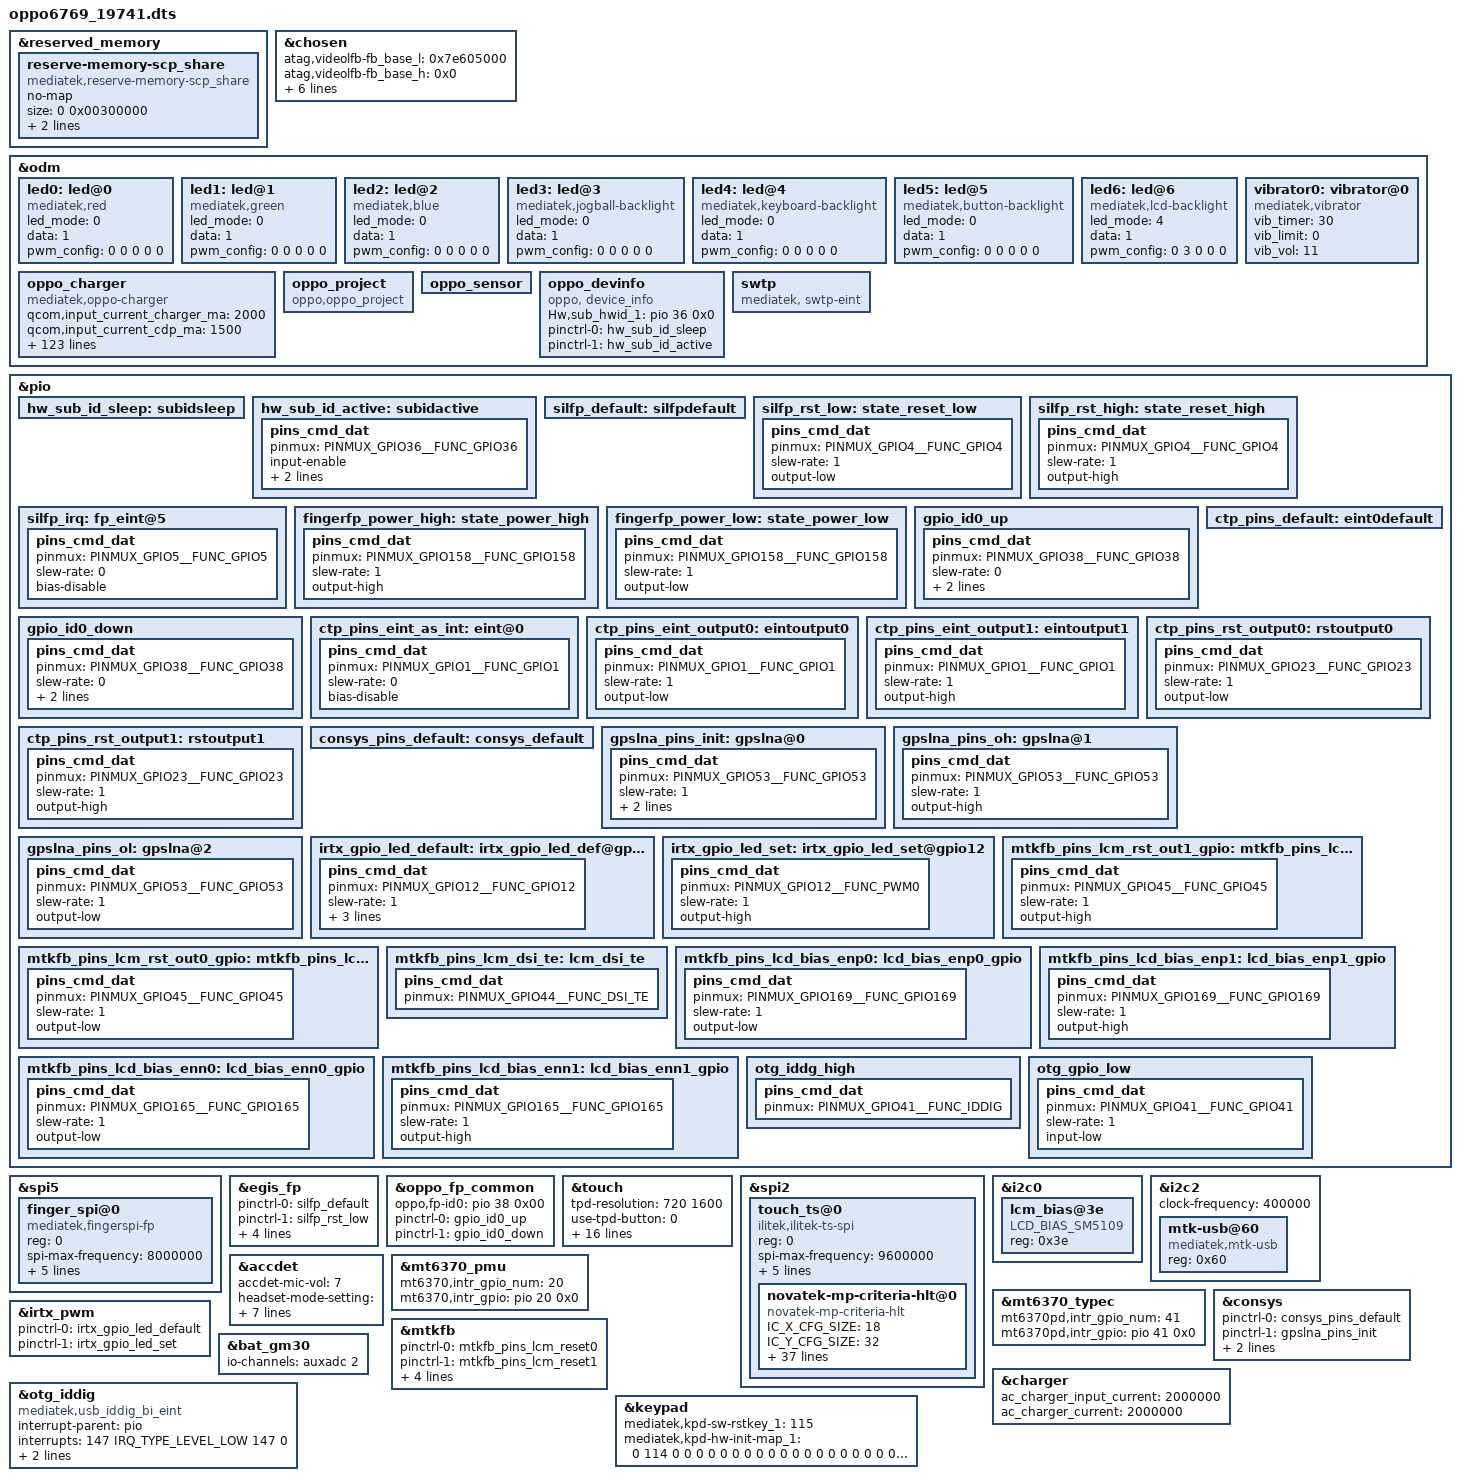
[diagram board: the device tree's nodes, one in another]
/*
 * Copyright (C) 2019 MediaTek Inc.
 *
 * This program is free software; you can redistribute it and/or modify
 * it under the terms of the GNU General Public License version 2 as
 * published by the Free Software Foundation.
 *
 * This program is distributed in the hope that it will be useful,
 * but WITHOUT ANY WARRANTY; without even the implied warranty of
 * MERCHANTABILITY or FITNESS FOR A PARTICULAR PURPOSE.
 * See http://www.gnu.org/licenses/gpl-2.0.html for more details.
 */

/dts-v1/;
/plugin/;
#include <dt-bindings/interrupt-controller/irq.h>
#include <dt-bindings/interrupt-controller/arm-gic.h>
#include <dt-bindings/pinctrl/mt6768-pinfunc.h>

&reserved_memory {
	reserve-memory-scp_share {
		compatible = "mediatek,reserve-memory-scp_share";
		no-map;
		size = <0 0x00300000>;
		alignment = <0 0x1000000>;
		alloc-ranges = <0 0x40000000 0 0x50000000>;
	};
};

/* chosen */
&chosen {

	atag,videolfb-fb_base_l = <0x7e605000>;
	atag,videolfb-fb_base_h = <0x0>;
	atag,videolfb-islcmfound = <1>;
	atag,videolfb-islcm_inited = <0>;
	atag,videolfb-fps= <6000>;
	atag,videolfb-vramSize= <0x017e8000>;
	atag,videolfb-lcmname=
		"hx83112b_fhdp_dsi_cmd_auo_rt5081_drv";
};

&odm {
	led0:led@0 {
		compatible = "mediatek,red";
		led_mode = <0>;
		data = <1>;
		pwm_config = <0 0 0 0 0>;
	};
	led1:led@1 {
		compatible = "mediatek,green";
		led_mode = <0>;
		data = <1>;
		pwm_config = <0 0 0 0 0>;
	};
	led2:led@2 {
		compatible = "mediatek,blue";
		led_mode = <0>;
		data = <1>;
		pwm_config = <0 0 0 0 0>;
	};
	led3:led@3 {
		compatible = "mediatek,jogball-backlight";
		led_mode = <0>;
		data = <1>;
		pwm_config = <0 0 0 0 0>;
	};
	led4:led@4 {
		compatible = "mediatek,keyboard-backlight";
		led_mode = <0>;
		data = <1>;
		pwm_config = <0 0 0 0 0>;
	};
	led5:led@5 {
		compatible = "mediatek,button-backlight";
		led_mode = <0>;
		data = <1>;
		pwm_config = <0 0 0 0 0>;
	};
	led6:led@6 {
		compatible = "mediatek,lcd-backlight";
		led_mode = <4>;
		data = <1>;
		pwm_config = <0 3 0 0 0>;
	};
	vibrator0:vibrator@0 {
		compatible = "mediatek,vibrator";
		/*
		vib_timer = <25>;
		vib_limit = <9>;
		vib_vol= <9>;
		*/
		vib_timer = <30>; /*xing.xiong@BSP.Kernel.Driver, 2018/12/08, Add for vibrator*/
		vib_limit = <0>;
		vib_vol= <11>;
	};
//#ifdef ODM_WT_EDIT
/*Sidong.Zhao@ODM_WT.BSP.CHG 2019/11/4,add oppo charge framework*/
	oppo_charger: oppo_charger {
		compatible = "mediatek,oppo-charger";
		//pinctrl-names = "default", "charger_gpio_as_output_low", "charger_gpio_as_output_high", "ship_sleep", "ship_active", "shortc_active";
		//pinctrl-0 = <&charger_pins_default>;
		//pinctrl-1 = <&charger_pins_eint_output0>;
		//pinctrl-2 = <&charger_pins_eint_output1>;
		//pinctrl-3 = <&ship_sleep_gpio>;
		//pinctrl-4 = <&ship_active_gpio>;
		//pinctrl-5 = <&shortc_active_gpio>;

		//for oppo chg framework:
		qcom,input_current_charger_ma = <2000>;
		qcom,input_current_cdp_ma = <1500>;
		qcom,input_current_usb_ma = <500>;
		qcom,input_current_led_ma = <1200>;
		qcom,input_current_led_ma_forcmcc = <500>;
		qcom,input_current_camera_ma = <1200>;
		qcom,input_current_calling_ma = <1200>;
		
		qcom,input_current_led_ma_high = <1200>;
		qcom,input_current_led_ma_warm = <1500>;
		qcom,input_current_led_ma_normal = <2000>;

		qcom,led_high_bat_decidegc = <370>;
		qcom,led_warm_bat_decidegc = <350>;

		qcom,iterm_disabled = <0>;
		qcom,iterm_ma = <265>;
		qcom,recharge-mv = <115>;

		qcom,batt_capacity_mah = <5000>; /*typical capacity*/
		//qcom,batt_capacity_mah = <3900>; /*rated capacity*/

		qcom,removed_bat_decidegc = <190>;  /* < -19C */

		qcom,cold_bat_decidegc = <20>;  /* -2C ~ 0C */
		qcom,temp_cold_vfloat_mv = <3980>;
		qcom,temp_cold_fastchg_current_ma = <350>;

		qcom,little_cold_bat_decidegc = <0>;	/* 0C ~ 5C */
		qcom,temp_little_cold_vfloat_mv = <4435>;
		qcom,temp_little_cold_fastchg_current_ma_high = <650>;
		qcom,temp_little_cold_fastchg_current_ma_low = <650>;
		qcom,temp_little_cold_fastchg_current_ma = <650>;
		monet,temp_little_cold_usbchg_current_ma_high = <650>;
		monet,temp_little_cold_usbchg_current_ma_low = <650>;
		monet,temp_little_cold_usbchg_current_ma = <650>;

		qcom,cool_bat_decidegc = <50>;	/* 5C ~ 12C */
		qcom,temp_cool_vfloat_mv = <4435>;
		qcom,temp_cool_fastchg_current_ma_high = <1350>;
		qcom,temp_cool_fastchg_current_ma_low = <650>;
		monet,temp_cool_usbchg_current_ma_high = <650>;
		monet,temp_cool_usbchg_current_ma_low = <550>;

		qcom,little_cool_bat_decidegc = <120>;	/* 12C ~ 16C */
		qcom,temp_little_cool_vfloat_mv = <4435>;
		qcom,temp_little_cool_fastchg_current_ma = <2050>;
		monet,temp_little_cool_usbchg_current_ma = <550>;

		qcom,normal_bat_decidegc = <160>;	/* 16C ~ 45C */
		qcom,temp_normal_fastchg_current_ma = <2200>;
		monet,temp_normal_usbchg_current_ma = <550>;
		qcom,temp_normal_vfloat_mv = <4435>;

		qcom,warm_bat_decidegc = <440>;		/* 44C ~ 53C */ /*8pin Bat Vooc project need add 3 degree C*/
		qcom,temp_warm_vfloat_mv = <4130>;
		qcom,temp_warm_fastchg_current_ma = <1350>;
		monet,temp_warm_usbchg_current_ma = <550>;
		qcom,temp_warm_fastchg_current_ma_led_on = <500>;

		qcom,hot_bat_decidegc = <530>;  /* > 53C */

		qcom,non_standard_vfloat_mv = <3980>;
		qcom,non_standard_fastchg_current_ma = <512>;

		qcom,short_c_bat_cv_mv = <4330>;
		qcom,short_c_bat_vfloat_mv = <3800>;
		qcom,short_c_bat_fastchg_current_ma = <512>;
		qcom,short_c_bat_vfloat_sw_limit = <3750>;

		qcom,cold_vfloat_sw_limit = <3930>;
		qcom,little_cold_vfloat_sw_limit = <4380>;
		qcom,cool_vfloat_sw_limit = <4380>;
		qcom,little_cool_vfloat_sw_limit = <4380>;
		qcom,normal_vfloat_sw_limit = <4380>;
		qcom,warm_vfloat_sw_limit = <4080>;
		qcom,non_standard_vfloat_sw_limit = <3930>;

		qcom,max_chg_time_sec = <36000>;
		qcom,charger_hv_thr = <5800>;
		qcom,charger_recv_thr = <5800>;
		qcom,charger_lv_thr = <3400>;
		qcom,vbatt_full_thr = <4400>;
		qcom,vbatt_hv_thr = <4550>;

		qcom,vfloat_step_mv = <10>;
		qcom,non_standard_vfloat_over_sw_limit = <4000>;
		qcom,cold_vfloat_over_sw_limit = <4000>;
		qcom,little_cold_vfloat_over_sw_limit = <4450>;
		qcom,cool_vfloat_over_sw_limit = <4450>;
		qcom,little_cool_vfloat_over_sw_limit = <4450>;
		qcom,normal_vfloat_over_sw_limit = <4450>;
		qcom,warm_vfloat_over_sw_limit = <4150>;

		qcom,vbatt_power_off = <3300>;
		qcom,vbatt_soc_1 = <3410>;
		qcom,vooc_project = <0>;
		qcom,vbatt_num = <1>;

		qcom,normal_vterm_hw_inc = <150>;
		qcom,non_normal_vterm_hw_inc = <10>;

		qcom,ff1_normal_fastchg_ma = <1088>;
		qcom,ffc2_normal_fastchg_ma = <780>;/*16C~35c*/
		qcom,ffc2_temp_warm_decidegc = <350>;
		qcom,ffc2_warm_fastchg_ma = <840>;/*35C~40c*/
		qcom,ffc2_temp_high_decidegc = <400>;
		qcom,ffc2_temp_low_decidegc = <120>;
		qcom,ff1_exit_step_ma = <488>;
		qcom,ff1_warm_exit_step_ma = <418>;
		qcom,ffc2_exit_step_ma = <180>;
		qcom,ffc2_warm_exit_step_ma = <170>;

		qcom,ffc_normal_vfloat_sw_limit = <4430>;
		qcom,ffc_temp_normal_vfloat_mv = <4500>;
		qcom,ffc_normal_vfloat_over_sw_limit = <4500>;

		qcom,default_iterm_ma = <265>;
		qcom,default_temp_normal_fastchg_current_ma = <2200>;
		qcom,default_normal_vfloat_sw_limit = <4380>;
		qcom,default_temp_normal_vfloat_mv = <4435>;
		qcom,default_normal_vfloat_over_sw_limit = <4450>;

		//for 2nd chip:
		qcom,iterm_ma_2nd = <300>;
		qcom,recharge-mv_2nd = <121>;

		qcom,temp_little_cold_vfloat_mv_2nd = <4391>;	/* 0C ~ 5C */
		qcom,temp_cool_vfloat_mv_2nd = <4391>;	/* 5C ~ 12C */
		qcom,temp_little_cool_vfloat_mv_2nd = <4391>;	/* 12C ~ 16C */
		qcom,temp_normal_vfloat_mv_2nd = <4391>;	/* 16C ~ 45C */

		qcom,little_cold_vfloat_over_sw_limit_2nd = <4395>;
		qcom,cool_vfloat_over_sw_limit_2nd = <4395>;
		qcom,little_cool_vfloat_over_sw_limit_2nd = <4395>;
		qcom,normal_vfloat_over_sw_limit_2nd = <4395>;

		qcom,default_iterm_ma_2nd = <300>;
		qcom,default_temp_normal_vfloat_mv_2nd = <4391>;
		qcom,default_normal_vfloat_over_sw_limit_2nd = <4395>;

		//for control:
		//qcom,suspend_after_full;
		qcom,check_batt_full_by_sw;
		//qcom,external_gauge;
		qcom,chg_ctrl_by_calling;
		qcom,chg_ctrl_by_lcd;
		qcom,chg_ctrl_by_camera;
		qcom,sw_vfloat_over_protect_enable;
		//qcom,ffc_support;

		//GPIO config:
		//qcom,chargerid_switch-gpio = <&pio 97 0x00>;
		//qcom,ship-gpio = <&pio 155 0x00>;
		//qcom,shortc-gpio = <&pio 77 0x00>;
	};
//#endif /*ODM_WT_EDIT*/
//#ifdef VENDOR_EDIT
/*Bin.Li@EXP.BSP.bootloader.bootflow, 2017/05/15, Add for oppo project */
	oppo_project:oppo_project {
		compatible = "oppo,oppo_project";
	};
//#endif /*VENDOR_EDIT*/
//#ifdef VENDOR_EDIT
/*Fei.Mo@PSW.BSP.Sensor, 2017/12/18, Add for sensor calibration paramaters */
       oppo_sensor:oppo_sensor {
       };
//#endif /*VENDOR_EDIT*

//#ifdef ODM_WT_EDIT
/*Junbo.Guo@ODM_WT.BSP.Kernel.Boot, 2019/10/29, Add for hardware id */
	oppo_devinfo:oppo_devinfo {
		compatible = "oppo, device_info";
		Hw,sub_hwid_1 =<&pio 36 0x0>;
		pinctrl-names = "hw_sub_id_sleep", "hw_sub_id_active";
		pinctrl-0 = <&hw_sub_id_sleep>;
		pinctrl-1 = <&hw_sub_id_active>;
		status = "okay";
	};
//#endif /*ODM_WT_EDIT*	
//#ifdef ODM_WT_EDIT
/*Yong.Cheng@ODM_WT.NW.RF.swtp, 2019/12/10, Add for swtp, RF cable detect */
	swtp:swtp {
		compatible = "mediatek, swtp-eint";
	};
//#endif /*ODM_WT_EDIT*	/
};

//#ifdef ODM_WT_EDIT
/*Junbo.Guo@ODM_WT.BSP.Kernel.Boot, 2019/10/29, Add for hardware id */
&pio{
	hw_sub_id_sleep: subidsleep {
	};
	hw_sub_id_active: subidactive {
		pins_cmd_dat {
			pinmux = <PINMUX_GPIO36__FUNC_GPIO36>;
			input-enable;
			slew-rate = <0>;
			bias-disable;
		};
	};
};
//#endif /*ODM_WT_EDIT*

//#ifdef VENDOR_EDIT
//Qingwen.Liu@RM.BSP.Fingerprint.Basic 2019/1/26 add for fpc fingerprint driver start
&spi5 {
	#address-cells = <1>;
	#size-cells = <0>;
	status = "okay";
	finger_spi@0 {
	    compatible = "mediatek,fingerspi-fp";
	    reg = <0>;
	    spi-max-frequency = <8000000>;
	    netlink-event = <30>;
	    spi-id = <1>;
	    spi-irq = <5>;
	    spi-reg = <0x11015000>;
	    spi-avdd-gpio = <158>;
        status = "okay";
    };
};

&egis_fp {
	pinctrl-names = "default", "rst-low", "rst-high",
	                "irq-init", "power_high","power_low";
	pinctrl-0 = <&silfp_default>;
	pinctrl-1 = <&silfp_rst_low>;
	pinctrl-2 = <&silfp_rst_high>;
	pinctrl-3 = <&silfp_irq>;
	pinctrl-4 = <&fingerfp_power_high>;
	pinctrl-5 = <&fingerfp_power_low>;
	status = "okay";
};

&pio {
	silfp_default: silfpdefault {
	};
	silfp_rst_low: state_reset_low {
		pins_cmd_dat {
			pinmux = <PINMUX_GPIO4__FUNC_GPIO4>;
			slew-rate = <1>;
			output-low;
		};
	};
	silfp_rst_high: state_reset_high {
		pins_cmd_dat {
			pinmux = <PINMUX_GPIO4__FUNC_GPIO4>;
			slew-rate = <1>;
			output-high;
		};
	};
	silfp_irq: fp_eint@5 {
		pins_cmd_dat {
			pinmux = <PINMUX_GPIO5__FUNC_GPIO5>;
			slew-rate = <0>;
			bias-disable;
		};
	};
	fingerfp_power_high: state_power_high {
		pins_cmd_dat {
			pinmux = <PINMUX_GPIO158__FUNC_GPIO158>;
			slew-rate = <1>;
			output-high;
		};
	};

	fingerfp_power_low: state_power_low {
		pins_cmd_dat {
			pinmux = <PINMUX_GPIO158__FUNC_GPIO158>;
			slew-rate = <1>;
			output-low;
		};
	};
};

/*the id config to project dts.*/
&pio{
	gpio_id0_up: gpio_id0_up {
		pins_cmd_dat {
			pinmux = <PINMUX_GPIO38__FUNC_GPIO38>;
			slew-rate = <0>;
			bias-pull-up;
			input-enable;
		};
	};
	gpio_id0_down: gpio_id0_down {
		pins_cmd_dat {
			pinmux = <PINMUX_GPIO38__FUNC_GPIO38>;
			slew-rate = <0>;
			bias-pull-down;
			input-enable;
		};
	};
};

&oppo_fp_common {
	oppo,fp-id0 = <&pio 38 0x00>;
	pinctrl-names = "gpio_id0_up","gpio_id0_down";
	pinctrl-0 = <&gpio_id0_up>;
	pinctrl-1 = <&gpio_id0_down>;
	status = "okay";
};
//Qingwen.Liu@RM.BSP.Fingerprint.Basic 2019/1/26 add for fpc fingerprint driver end
//#endif //VENDOR_EDIT

/* TOUCH start */
&touch {
	tpd-resolution = <720 1600>;
	use-tpd-button = <0>;
	tpd-key-num = <3>;
	tpd-key-local= <139 172 158 0>;
	tpd-key-dim-local = <90 883 100 40 230
				883 100 40 370 883 100 40 0 0 0 0>;
	tpd-max-touch-num = <10>;
	tpd-filter-enable = <0>;
	tpd-filter-pixel-density = <168>;
	tpd-filter-custom-prameters = <0 0 0 0 0 0 0 0 0 0 0 0>;
	tpd-filter-custom-speed = <0 0 0>;
	pinctrl-names = "default", "state_eint_as_int",
		"state_eint_output0", "state_eint_output1",
		"state_rst_output0", "state_rst_output1";
	pinctrl-0 = <&ctp_pins_default>;
	pinctrl-1 = <&ctp_pins_eint_as_int>;
	pinctrl-2 = <&ctp_pins_eint_output0>;
	pinctrl-3 = <&ctp_pins_eint_output1>;
	pinctrl-4 = <&ctp_pins_rst_output0>;
	pinctrl-5 = <&ctp_pins_rst_output1>;
	status = "okay";
};
&pio {
	ctp_pins_default: eint0default {
	};
	ctp_pins_eint_as_int: eint@0 {
		pins_cmd_dat {
			pinmux = <PINMUX_GPIO1__FUNC_GPIO1>;
			slew-rate = <0>;
			bias-disable;
		};
	};
	ctp_pins_eint_output0: eintoutput0 {
		pins_cmd_dat {
			pinmux = <PINMUX_GPIO1__FUNC_GPIO1>;
			slew-rate = <1>;
			output-low;
		};
	};
	ctp_pins_eint_output1: eintoutput1 {
		pins_cmd_dat {
			pinmux = <PINMUX_GPIO1__FUNC_GPIO1>;
			slew-rate = <1>;
			output-high;
	};
	};
	ctp_pins_rst_output0: rstoutput0 {
		pins_cmd_dat {
			pinmux = <PINMUX_GPIO23__FUNC_GPIO23>;
			slew-rate = <1>;
			output-low;
		};
	};
	ctp_pins_rst_output1: rstoutput1 {
		pins_cmd_dat {
			pinmux = <PINMUX_GPIO23__FUNC_GPIO23>;
			slew-rate = <1>;
			output-high;
		};
	};
};
//#ifdef ODM_WT_EDIT
//#Tongxing.Liu@ODM_WT.BSP.Touchscreen.Base,2019/10/04,bringup add for xl and hlt touchscreen mould dts config.
&spi2 {
    #address-cells = <1>;
    #size-cells = <0>;
    touch_ts@0 {
        reg = <0>;
        compatible = "ilitek,ilitek-ts-spi","novatek,NVT-ts-spi";
	status = "okay";
	/* touch spi config */
        spi-max-frequency = <9600000>;
	/* novatek touch gpio config */
	novatek,irq-gpio = <&pio 1 0>;
	novatek,reset-gpio = <&pio 23 0>;
	novatek,reset_global_gpio = <&pio 45 0>;
	/* 672A, 525B */
	novatek,swrst-n8-addr = <0x03F0FE>;
	/* MP config  */
	novatek,mp-support-dt;
	novatek-mp-criteria-hlt@0 {
		#address-cells = <1>;
		#size-cells = <0>;
		compatible = "novatek-mp-criteria-hlt";
	        /* MP Config */
		IC_X_CFG_SIZE = <18>;
		IC_Y_CFG_SIZE = <32>;
		IC_KEY_CFG_SIZE = <4>;
		X_Channel = <18>;
		Y_Channel = <32>;
		AIN_X = <0 1 2 3 4 5 6 7 8 9 10 11 12 13 14 15 16 17>;
		AIN_Y = <0 1 2 3 4 5 6 7 8 9 10 11 12 13 14 15 16 17 18 19
							20 21 22 23 24 25 26 27 28 29 30 31>;
		AIN_KEY = <0 1 2 0xFF>;

		/* MP Criteria */
		PS_Config_Lmt_Short_Rawdata_P = <
			14008 14008 14008 14008 14008 14008 14008 14008 14008 14008 14008 14008 14008 14008 14008 14008 14008 14008
			14008 14008 14008 14008 14008 14008 14008 14008 14008 14008 14008 14008 14008 14008 14008 14008 14008 14008
			14008 14008 14008 14008 14008 14008 14008 14008 14008 14008 14008 14008 14008 14008 14008 14008 14008 14008
			14008 14008 14008 14008 14008 14008 14008 14008 14008 14008 14008 14008 14008 14008 14008 14008 14008 14008
			14008 14008 14008 14008 14008 14008 14008 14008 14008 14008 14008 14008 14008 14008 14008 14008 14008 14008
			14008 14008 14008 14008 14008 14008 14008 14008 14008 14008 14008 14008 14008 14008 14008 14008 14008 14008
			14008 14008 14008 14008 14008 14008 14008 14008 14008 14008 14008 14008 14008 14008 14008 14008 14008 14008
			14008 14008 14008 14008 14008 14008 14008 14008 14008 14008 14008 14008 14008 14008 14008 14008 14008 14008
			14008 14008 14008 14008 14008 14008 14008 14008 14008 14008 14008 14008 14008 14008 14008 14008 14008 14008
			14008 14008 14008 14008 14008 14008 14008 14008 14008 14008 14008 14008 14008 14008 14008 14008 14008 14008
			14008 14008 14008 14008 14008 14008 14008 14008 14008 14008 14008 14008 14008 14008 14008 14008 14008 14008
			14008 14008 14008 14008 14008 14008 14008 14008 14008 14008 14008 14008 14008 14008 14008 14008 14008 14008
			14008 14008 14008 14008 14008 14008 14008 14008 14008 14008 14008 14008 14008 14008 14008 14008 14008 14008
			14008 14008 14008 14008 14008 14008 14008 14008 14008 14008 14008 14008 14008 14008 14008 14008 14008 14008
			14008 14008 14008 14008 14008 14008 14008 14008 14008 14008 14008 14008 14008 14008 14008 14008 14008 14008
			14008 14008 14008 14008 14008 14008 14008 14008 14008 14008 14008 14008 14008 14008 14008 14008 14008 14008
			14008 14008 14008 14008 14008 14008 14008 14008 14008 14008 14008 14008 14008 14008 14008 14008 14008 14008
			14008 14008 14008 14008 14008 14008 14008 14008 14008 14008 14008 14008 14008 14008 14008 14008 14008 14008
			14008 14008 14008 14008 14008 14008 14008 14008 14008 14008 14008 14008 14008 14008 14008 14008 14008 14008
			14008 14008 14008 14008 14008 14008 14008 14008 14008 14008 14008 14008 14008 14008 14008 14008 14008 14008
			14008 14008 14008 14008 14008 14008 14008 14008 14008 14008 14008 14008 14008 14008 14008 14008 14008 14008
			14008 14008 14008 14008 14008 14008 14008 14008 14008 14008 14008 14008 14008 14008 14008 14008 14008 14008
			14008 14008 14008 14008 14008 14008 14008 14008 14008 14008 14008 14008 14008 14008 14008 14008 14008 14008
			14008 14008 14008 14008 14008 14008 14008 14008 14008 14008 14008 14008 14008 14008 14008 14008 14008 14008
			14008 14008 14008 14008 14008 14008 14008 14008 14008 14008 14008 14008 14008 14008 14008 14008 14008 14008
			14008 14008 14008 14008 14008 14008 14008 14008 14008 14008 14008 14008 14008 14008 14008 14008 14008 14008
			14008 14008 14008 14008 14008 14008 14008 14008 14008 14008 14008 14008 14008 14008 14008 14008 14008 14008
			14008 14008 14008 14008 14008 14008 14008 14008 14008 14008 14008 14008 14008 14008 14008 14008 14008 14008
			14008 14008 14008 14008 14008 14008 14008 14008 14008 14008 14008 14008 14008 14008 14008 14008 14008 14008
			14008 14008 14008 14008 14008 14008 14008 14008 14008 14008 14008 14008 14008 14008 14008 14008 14008 14008
			14008 14008 14008 14008 14008 14008 14008 14008 14008 14008 14008 14008 14008 14008 14008 14008 14008 14008
			14008 14008 14008 14008 14008 14008 14008 14008 14008 14008 14008 14008 14008 14008 14008 14008 14008 14008
			>;

		PS_Config_Lmt_Short_Rawdata_N = <
			10000 10000 10000 10000 10000 10000 10000 10000 10000 10000 10000 10000 10000 10000 10000 10000 10000 10000
			10000 10000 10000 10000 10000 10000 10000 10000 10000 10000 10000 10000 10000 10000 10000 10000 10000 10000
			10000 10000 10000 10000 10000 10000 10000 10000 10000 10000 10000 10000 10000 10000 10000 10000 10000 10000
			10000 10000 10000 10000 10000 10000 10000 10000 10000 10000 10000 10000 10000 10000 10000 10000 10000 10000
			10000 10000 10000 10000 10000 10000 10000 10000 10000 10000 10000 10000 10000 10000 10000 10000 10000 10000
			10000 10000 10000 10000 10000 10000 10000 10000 10000 10000 10000 10000 10000 10000 10000 10000 10000 10000
			10000 10000 10000 10000 10000 10000 10000 10000 10000 10000 10000 10000 10000 10000 10000 10000 10000 10000
			10000 10000 10000 10000 10000 10000 10000 10000 10000 10000 10000 10000 10000 10000 10000 10000 10000 10000
			10000 10000 10000 10000 10000 10000 10000 10000 10000 10000 10000 10000 10000 10000 10000 10000 10000 10000
			10000 10000 10000 10000 10000 10000 10000 10000 10000 10000 10000 10000 10000 10000 10000 10000 10000 10000
			10000 10000 10000 10000 10000 10000 10000 10000 10000 10000 10000 10000 10000 10000 10000 10000 10000 10000
			10000 10000 10000 10000 10000 10000 10000 10000 10000 10000 10000 10000 10000 10000 10000 10000 10000 10000
			10000 10000 10000 10000 10000 10000 10000 10000 10000 10000 10000 10000 10000 10000 10000 10000 10000 10000
			10000 10000 10000 10000 10000 10000 10000 10000 10000 10000 10000 10000 10000 10000 10000 10000 10000 10000
			10000 10000 10000 10000 10000 10000 10000 10000 10000 10000 10000 10000 10000 10000 10000 10000 10000 10000
			10000 10000 10000 10000 10000 10000 10000 10000 10000 10000 10000 10000 10000 10000 10000 10000 10000 10000
			10000 10000 10000 10000 10000 10000 10000 10000 10000 10000 10000 10000 10000 10000 10000 10000 10000 10000
			10000 10000 10000 10000 10000 10000 10000 10000 10000 10000 10000 10000 10000 10000 10000 10000 10000 10000
			10000 10000 10000 10000 10000 10000 10000 10000 10000 10000 10000 10000 10000 10000 10000 10000 10000 10000
			10000 10000 10000 10000 10000 10000 10000 10000 10000 10000 10000 10000 10000 10000 10000 10000 10000 10000
			10000 10000 10000 10000 10000 10000 10000 10000 10000 10000 10000 10000 10000 10000 10000 10000 10000 10000
			10000 10000 10000 10000 10000 10000 10000 10000 10000 10000 10000 10000 10000 10000 10000 10000 10000 10000
			10000 10000 10000 10000 10000 10000 10000 10000 10000 10000 10000 10000 10000 10000 10000 10000 10000 10000
			10000 10000 10000 10000 10000 10000 10000 10000 10000 10000 10000 10000 10000 10000 10000 10000 10000 10000
			10000 10000 10000 10000 10000 10000 10000 10000 10000 10000 10000 10000 10000 10000 10000 10000 10000 10000
			10000 10000 10000 10000 10000 10000 10000 10000 10000 10000 10000 10000 10000 10000 10000 10000 10000 10000
			10000 10000 10000 10000 10000 10000 10000 10000 10000 10000 10000 10000 10000 10000 10000 10000 10000 10000
			10000 10000 10000 10000 10000 10000 10000 10000 10000 10000 10000 10000 10000 10000 10000 10000 10000 10000
			10000 10000 10000 10000 10000 10000 10000 10000 10000 10000 10000 10000 10000 10000 10000 10000 10000 10000
			10000 10000 10000 10000 10000 10000 10000 10000 10000 10000 10000 10000 10000 10000 10000 10000 10000 10000
			10000 10000 10000 10000 10000 10000 10000 10000 10000 10000 10000 10000 10000 10000 10000 10000 10000 10000
			10000 10000 10000 10000 10000 10000 10000 10000 10000 10000 10000 10000 10000 10000 10000 10000 10000 10000
			>;

		PS_Config_Lmt_Open_Rawdata_P = <
			4096 4096 4096 4096 4096 4096 4096 4096 4096 4096 4096 4096 4096 4096 4096 4096 4096 4096
			4096 4096 4096 4096 4096 4096 4096 4096 4096 4096 4096 4096 4096 4096 4096 4096 4096 4096
			4096 4096 4096 4096 4096 4096 4096 4096 4096 4096 4096 4096 4096 4096 4096 4096 4096 4096
			4096 4096 4096 4096 4096 4096 4096 4096 4096 4096 4096 4096 4096 4096 4096 4096 4096 4096
			4096 4096 4096 4096 4096 4096 4096 4096 4096 4096 4096 4096 4096 4096 4096 4096 4096 4096
			4096 4096 4096 4096 4096 4096 4096 4096 4096 4096 4096 4096 4096 4096 4096 4096 4096 4096
			4096 4096 4096 4096 4096 4096 4096 4096 4096 4096 4096 4096 4096 4096 4096 4096 4096 4096
			4096 4096 4096 4096 4096 4096 4096 4096 4096 4096 4096 4096 4096 4096 4096 4096 4096 4096
			4096 4096 4096 4096 4096 4096 4096 4096 4096 4096 4096 4096 4096 4096 4096 4096 4096 4096
			4096 4096 4096 4096 4096 4096 4096 4096 4096 4096 4096 4096 4096 4096 4096 4096 4096 4096
			4096 4096 4096 4096 4096 4096 4096 4096 4096 4096 4096 4096 4096 4096 4096 4096 4096 4096
			4096 4096 4096 4096 4096 4096 4096 4096 4096 4096 4096 4096 4096 4096 4096 4096 4096 4096
			4096 4096 4096 4096 4096 4096 4096 4096 4096 4096 4096 4096 4096 4096 4096 4096 4096 4096
			4096 4096 4096 4096 4096 4096 4096 4096 4096 4096 4096 4096 4096 4096 4096 4096 4096 4096
			4096 4096 4096 4096 4096 4096 4096 4096 4096 4096 4096 4096 4096 4096 4096 4096 4096 4096
			4096 4096 4096 4096 4096 4096 4096 4096 4096 4096 4096 4096 4096 4096 4096 4096 4096 4096
			4096 4096 4096 4096 4096 4096 4096 4096 4096 4096 4096 4096 4096 4096 4096 4096 4096 4096
			4096 4096 4096 4096 4096 4096 4096 4096 4096 4096 4096 4096 4096 4096 4096 4096 4096 4096
			4096 4096 4096 4096 4096 4096 4096 4096 4096 4096 4096 4096 4096 4096 4096 4096 4096 4096
			4096 4096 4096 4096 4096 4096 4096 4096 4096 4096 4096 4096 4096 4096 4096 4096 4096 4096
			4096 4096 4096 4096 4096 4096 4096 4096 4096 4096 4096 4096 4096 4096 4096 4096 4096 4096
			4096 4096 4096 4096 4096 4096 4096 4096 4096 4096 4096 4096 4096 4096 4096 4096 4096 4096
			4096 4096 4096 4096 4096 4096 4096 4096 4096 4096 4096 4096 4096 4096 4096 4096 4096 4096
			4096 4096 4096 4096 4096 4096 4096 4096 4096 4096 4096 4096 4096 4096 4096 4096 4096 4096
			4096 4096 4096 4096 4096 4096 4096 4096 4096 4096 4096 4096 4096 4096 4096 4096 4096 4096
			4096 4096 4096 4096 4096 4096 4096 4096 4096 4096 4096 4096 4096 4096 4096 4096 4096 4096
			4096 4096 4096 4096 4096 4096 4096 4096 4096 4096 4096 4096 4096 4096 4096 4096 4096 4096
			4096 4096 4096 4096 4096 4096 4096 4096 4096 4096 4096 4096 4096 4096 4096 4096 4096 4096
			4096 4096 4096 4096 4096 4096 4096 4096 4096 4096 4096 4096 4096 4096 4096 4096 4096 4096
			4096 4096 4096 4096 4096 4096 4096 4096 4096 4096 4096 4096 4096 4096 4096 4096 4096 4096
			4096 4096 4096 4096 4096 4096 4096 4096 4096 4096 4096 4096 4096 4096 4096 4096 4096 4096
			4096 4096 4096 4096 4096 4096 4096 4096 4096 4096 4096 4096 4096 4096 4096 4096 4096 4096
			>;

		PS_Config_Lmt_Open_Rawdata_N = <
			50 50 50 50 50 50 50 50 50 50 50 50 50 50 50 50 50 50
			50 50 50 50 50 50 50 50 50 50 50 50 50 50 50 50 50 50
			50 50 50 50 50 50 50 50 50 50 50 50 50 50 50 50 50 50
			50 50 50 50 50 50 50 50 50 50 50 50 50 50 50 50 50 50
			50 50 50 50 50 50 50 50 50 50 50 50 50 50 50 50 50 50
			50 50 50 50 50 50 50 50 50 50 50 50 50 50 50 50 50 50
			50 50 50 50 50 50 50 50 50 50 50 50 50 50 50 50 50 50
			50 50 50 50 50 50 50 50 50 50 50 50 50 50 50 50 50 50
			50 50 50 50 50 50 50 50 50 50 50 50 50 50 50 50 50 50
			50 50 50 50 50 50 50 50 50 50 50 50 50 50 50 50 50 50
			50 50 50 50 50 50 50 50 50 50 50 50 50 50 50 50 50 50
			50 50 50 50 50 50 50 50 50 50 50 50 50 50 50 50 50 50
			50 50 50 50 50 50 50 50 50 50 50 50 50 50 50 50 50 50
			50 50 50 50 50 50 50 50 50 50 50 50 50 50 50 50 50 50
			50 50 50 50 50 50 50 50 50 50 50 50 50 50 50 50 50 50
			50 50 50 50 50 50 50 50 50 50 50 50 50 50 50 50 50 50
			50 50 50 50 50 50 50 50 50 50 50 50 50 50 50 50 50 50
			50 50 50 50 50 50 50 50 50 50 50 50 50 50 50 50 50 50
			50 50 50 50 50 50 50 50 50 50 50 50 50 50 50 50 50 50
			50 50 50 50 50 50 50 50 50 50 50 50 50 50 50 50 50 50
			50 50 50 50 50 50 50 50 50 50 50 50 50 50 50 50 50 50
			50 50 50 50 50 50 50 50 50 50 50 50 50 50 50 50 50 50
			50 50 50 50 50 50 50 50 50 50 50 50 50 50 50 50 50 50
			50 50 50 50 50 50 50 50 50 50 50 50 50 50 50 50 50 50
			50 50 50 50 50 50 50 50 50 50 50 50 50 50 50 50 50 50
			50 50 50 50 50 50 50 50 50 50 50 50 50 50 50 50 50 50
			50 50 50 50 50 50 50 50 50 50 50 50 50 50 50 50 50 50
			50 50 50 50 50 50 50 50 50 50 50 50 50 50 50 50 50 50
			50 50 50 50 50 50 50 50 50 50 50 50 50 50 50 50 50 50
			50 50 50 50 50 50 50 50 50 50 50 50 50 50 50 50 50 50
			50 50 50 50 50 50 50 50 50 50 50 50 50 50 50 50 50 50
			50 50 50 50 50 50 50 50 50 50 50 50 50 50 50 50 50 50
			>;

		PS_Config_Lmt_FW_Rawdata_P = <
			1920 1920 1920 1920 1920 1920 1920 1920 1920 1920 1920 1920 1920 1920 1920 1920 1920 1920
			1920 1920 1920 1920 1920 1920 1920 1920 1920 1920 1920 1920 1920 1920 1920 1920 1920 1920
			1920 1920 1920 1920 1920 1920 1920 1920 1920 1920 1920 1920 1920 1920 1920 1920 1920 1920
			1920 1920 1920 1920 1920 1920 1920 1920 1920 1920 1920 1920 1920 1920 1920 1920 1920 1920
			1920 1920 1920 1920 1920 1920 1920 1920 1920 1920 1920 1920 1920 1920 1920 1920 1920 1920
			1920 1920 1920 1920 1920 1920 1920 1920 1920 1920 1920 1920 1920 1920 1920 1920 1920 1920
			1920 1920 1920 1920 1920 1920 1920 1920 1920 1920 1920 1920 1920 1920 1920 1920 1920 1920
			1920 1920 1920 1920 1920 1920 1920 1920 1920 1920 1920 1920 1920 1920 1920 1920 1920 1920
			1920 1920 1920 1920 1920 1920 1920 1920 1920 1920 1920 1920 1920 1920 1920 1920 1920 1920
			1920 1920 1920 1920 1920 1920 1920 1920 1920 1920 1920 1920 1920 1920 1920 1920 1920 1920
			1920 1920 1920 1920 1920 1920 1920 1920 1920 1920 1920 1920 1920 1920 1920 1920 1920 1920
			1920 1920 1920 1920 1920 1920 1920 1920 1920 1920 1920 1920 1920 1920 1920 1920 1920 1920
			1920 1920 1920 1920 1920 1920 1920 1920 1920 1920 1920 1920 1920 1920 1920 1920 1920 1920
			1920 1920 1920 1920 1920 1920 1920 1920 1920 1920 1920 1920 1920 1920 1920 1920 1920 1920
			1920 1920 1920 1920 1920 1920 1920 1920 1920 1920 1920 1920 1920 1920 1920 1920 1920 1920
			1920 1920 1920 1920 1920 1920 1920 1920 1920 1920 1920 1920 1920 1920 1920 1920 1920 1920
			1920 1920 1920 1920 1920 1920 1920 1920 1920 1920 1920 1920 1920 1920 1920 1920 1920 1920
			1920 1920 1920 1920 1920 1920 1920 1920 1920 1920 1920 1920 1920 1920 1920 1920 1920 1920
			1920 1920 1920 1920 1920 1920 1920 1920 1920 1920 1920 1920 1920 1920 1920 1920 1920 1920
			1920 1920 1920 1920 1920 1920 1920 1920 1920 1920 1920 1920 1920 1920 1920 1920 1920 1920
			1920 1920 1920 1920 1920 1920 1920 1920 1920 1920 1920 1920 1920 1920 1920 1920 1920 1920
			1920 1920 1920 1920 1920 1920 1920 1920 1920 1920 1920 1920 1920 1920 1920 1920 1920 1920
			1920 1920 1920 1920 1920 1920 1920 1920 1920 1920 1920 1920 1920 1920 1920 1920 1920 1920
			1920 1920 1920 1920 1920 1920 1920 1920 1920 1920 1920 1920 1920 1920 1920 1920 1920 1920
			1920 1920 1920 1920 1920 1920 1920 1920 1920 1920 1920 1920 1920 1920 1920 1920 1920 1920
			1920 1920 1920 1920 1920 1920 1920 1920 1920 1920 1920 1920 1920 1920 1920 1920 1920 1920
			1920 1920 1920 1920 1920 1920 1920 1920 1920 1920 1920 1920 1920 1920 1920 1920 1920 1920
			1920 1920 1920 1920 1920 1920 1920 1920 1920 1920 1920 1920 1920 1920 1920 1920 1920 1920
			1920 1920 1920 1920 1920 1920 1920 1920 1920 1920 1920 1920 1920 1920 1920 1920 1920 1920
			1920 1920 1920 1920 1920 1920 1920 1920 1920 1920 1920 1920 1920 1920 1920 1920 1920 1920
			1920 1920 1920 1920 1920 1920 1920 1920 1920 1920 1920 1920 1920 1920 1920 1920 1920 1920
			1920 1920 1920 1920 1920 1920 1920 1920 1920 1920 1920 1920 1920 1920 1920 1920 1920 1920
			>;

		PS_Config_Lmt_FW_Rawdata_N = <
			240 240 240 240 240 240 240 240 240 240 240 240 240 240 240 240 240 240
			240 240 240 240 240 240 240 240 240 240 240 240 240 240 240 240 240 240
			240 240 240 240 240 240 240 240 240 240 240 240 240 240 240 240 240 240
			240 240 240 240 240 240 240 240 240 240 240 240 240 240 240 240 240 240
			240 240 240 240 240 240 240 240 240 240 240 240 240 240 240 240 240 240
			240 240 240 240 240 240 240 240 240 240 240 240 240 240 240 240 240 240
			240 240 240 240 240 240 240 240 240 240 240 240 240 240 240 240 240 240
			240 240 240 240 240 240 240 240 240 240 240 240 240 240 240 240 240 240
			240 240 240 240 240 240 240 240 240 240 240 240 240 240 240 240 240 240
			240 240 240 240 240 240 240 240 240 240 240 240 240 240 240 240 240 240
			240 240 240 240 240 240 240 240 240 240 240 240 240 240 240 240 240 240
			240 240 240 240 240 240 240 240 240 240 240 240 240 240 240 240 240 240
			240 240 240 240 240 240 240 240 240 240 240 240 240 240 240 240 240 240
			240 240 240 240 240 240 240 240 240 240 240 240 240 240 240 240 240 240
			240 240 240 240 240 240 240 240 240 240 240 240 240 240 240 240 240 240
			240 240 240 240 240 240 240 240 240 240 240 240 240 240 240 240 240 240
			240 240 240 240 240 240 240 240 240 240 240 240 240 240 240 240 240 240
			240 240 240 240 240 240 240 240 240 240 240 240 240 240 240 240 240 240
			240 240 240 240 240 240 240 240 240 240 240 240 240 240 240 240 240 240
			240 240 240 240 240 240 240 240 240 240 240 240 240 240 240 240 240 240
			240 240 240 240 240 240 240 240 240 240 240 240 240 240 240 240 240 240
			240 240 240 240 240 240 240 240 240 240 240 240 240 240 240 240 240 240
			240 240 240 240 240 240 240 240 240 240 240 240 240 240 240 240 240 240
			240 240 240 240 240 240 240 240 240 240 240 240 240 240 240 240 240 240
			240 240 240 240 240 240 240 240 240 240 240 240 240 240 240 240 240 240
			240 240 240 240 240 240 240 240 240 240 240 240 240 240 240 240 240 240
			240 240 240 240 240 240 240 240 240 240 240 240 240 240 240 240 240 240
			240 240 240 240 240 240 240 240 240 240 240 240 240 240 240 240 240 240
			240 240 240 240 240 240 240 240 240 240 240 240 240 240 240 240 240 240
			240 240 240 240 240 240 240 240 240 240 240 240 240 240 240 240 240 240
			240 240 240 240 240 240 240 240 240 240 240 240 240 240 240 240 240 240
			240 240 240 240 240 240 240 240 240 240 240 240 240 240 240 240 240 240
			>;

		PS_Config_Lmt_FW_CC_P = <
			314 314 314 314 314 314 314 314 314 314 314 314 314 314 314 314 314 314
			314 314 314 314 314 314 314 314 314 314 314 314 314 314 314 314 314 314
			314 314 314 314 314 314 314 314 314 314 314 314 314 314 314 314 314 314
			314 314 314 314 314 314 314 314 314 314 314 314 314 314 314 314 314 314
			314 314 314 314 314 314 314 314 314 314 314 314 314 314 314 314 314 314
			314 314 314 314 314 314 314 314 314 314 314 314 314 314 314 314 314 314
			314 314 314 314 314 314 314 314 314 314 314 314 314 314 314 314 314 314
			314 314 314 314 314 314 314 314 314 314 314 314 314 314 314 314 314 314
			314 314 314 314 314 314 314 314 314 314 314 314 314 314 314 314 314 314
			314 314 314 314 314 314 314 314 314 314 314 314 314 314 314 314 314 314
			314 314 314 314 314 314 314 314 314 314 314 314 314 314 314 314 314 314
			314 314 314 314 314 314 314 314 314 314 314 314 314 314 314 314 314 314
			314 314 314 314 314 314 314 314 314 314 314 314 314 314 314 314 314 314
			314 314 314 314 314 314 314 314 314 314 314 314 314 314 314 314 314 314
			314 314 314 314 314 314 314 314 314 314 314 314 314 314 314 314 314 314
			314 314 314 314 314 314 314 314 314 314 314 314 314 314 314 314 314 314
			314 314 314 314 314 314 314 314 314 314 314 314 314 314 314 314 314 314
			314 314 314 314 314 314 314 314 314 314 314 314 314 314 314 314 314 314
			314 314 314 314 314 314 314 314 314 314 314 314 314 314 314 314 314 314
			314 314 314 314 314 314 314 314 314 314 314 314 314 314 314 314 314 314
			314 314 314 314 314 314 314 314 314 314 314 314 314 314 314 314 314 314
			314 314 314 314 314 314 314 314 314 314 314 314 314 314 314 314 314 314
			314 314 314 314 314 314 314 314 314 314 314 314 314 314 314 314 314 314
			314 314 314 314 314 314 314 314 314 314 314 314 314 314 314 314 314 314
			314 314 314 314 314 314 314 314 314 314 314 314 314 314 314 314 314 314
			314 314 314 314 314 314 314 314 314 314 314 314 314 314 314 314 314 314
			314 314 314 314 314 314 314 314 314 314 314 314 314 314 314 314 314 314
			314 314 314 314 314 314 314 314 314 314 314 314 314 314 314 314 314 314
			314 314 314 314 314 314 314 314 314 314 314 314 314 314 314 314 314 314
			314 314 314 314 314 314 314 314 314 314 314 314 314 314 314 314 314 314
			314 314 314 314 314 314 314 314 314 314 314 314 314 314 314 314 314 314
			314 314 314 314 314 314 314 314 314 314 314 314 314 314 314 314 314 314
			>;

		PS_Config_Lmt_FW_CC_N = <
			30 30 30 30 30 30 30 30 30 30 30 30 30 30 30 30 30 30
			30 30 30 30 30 30 30 30 30 30 30 30 30 30 30 30 30 30
			30 30 30 30 30 30 30 30 30 30 30 30 30 30 30 30 30 30
			30 30 30 30 30 30 30 30 30 30 30 30 30 30 30 30 30 30
			30 30 30 30 30 30 30 30 30 30 30 30 30 30 30 30 30 30
			30 30 30 30 30 30 30 30 30 30 30 30 30 30 30 30 30 30
			30 30 30 30 30 30 30 30 30 30 30 30 30 30 30 30 30 30
			30 30 30 30 30 30 30 30 30 30 30 30 30 30 30 30 30 30
			30 30 30 30 30 30 30 30 30 30 30 30 30 30 30 30 30 30
			30 30 30 30 30 30 30 30 30 30 30 30 30 30 30 30 30 30
			30 30 30 30 30 30 30 30 30 30 30 30 30 30 30 30 30 30
			30 30 30 30 30 30 30 30 30 30 30 30 30 30 30 30 30 30
			30 30 30 30 30 30 30 30 30 30 30 30 30 30 30 30 30 30
			30 30 30 30 30 30 30 30 30 30 30 30 30 30 30 30 30 30
			30 30 30 30 30 30 30 30 30 30 30 30 30 30 30 30 30 30
			30 30 30 30 30 30 30 30 30 30 30 30 30 30 30 30 30 30
			30 30 30 30 30 30 30 30 30 30 30 30 30 30 30 30 30 30
			30 30 30 30 30 30 30 30 30 30 30 30 30 30 30 30 30 30
			30 30 30 30 30 30 30 30 30 30 30 30 30 30 30 30 30 30
			30 30 30 30 30 30 30 30 30 30 30 30 30 30 30 30 30 30
			30 30 30 30 30 30 30 30 30 30 30 30 30 30 30 30 30 30
			30 30 30 30 30 30 30 30 30 30 30 30 30 30 30 30 30 30
			30 30 30 30 30 30 30 30 30 30 30 30 30 30 30 30 30 30
			30 30 30 30 30 30 30 30 30 30 30 30 30 30 30 30 30 30
			30 30 30 30 30 30 30 30 30 30 30 30 30 30 30 30 30 30
			30 30 30 30 30 30 30 30 30 30 30 30 30 30 30 30 30 30
			30 30 30 30 30 30 30 30 30 30 30 30 30 30 30 30 30 30
			30 30 30 30 30 30 30 30 30 30 30 30 30 30 30 30 30 30
			30 30 30 30 30 30 30 30 30 30 30 30 30 30 30 30 30 30
			30 30 30 30 30 30 30 30 30 30 30 30 30 30 30 30 30 30
			30 30 30 30 30 30 30 30 30 30 30 30 30 30 30 30 30 30
			30 30 30 30 30 30 30 30 30 30 30 30 30 30 30 30 30 30
			>;

		PS_Config_Lmt_FW_Diff_P = <
			75 75 75 75 75 75 75 75 75 75 75 75 75 75 75 75 75 75
			75 75 75 75 75 75 75 75 75 75 75 75 75 75 75 75 75 75
			75 75 75 75 75 75 75 75 75 75 75 75 75 75 75 75 75 75
			75 75 75 75 75 75 75 75 75 75 75 75 75 75 75 75 75 75
			75 75 75 75 75 75 75 75 75 75 75 75 75 75 75 75 75 75
			75 75 75 75 75 75 75 75 75 75 75 75 75 75 75 75 75 75
			75 75 75 75 75 75 75 75 75 75 75 75 75 75 75 75 75 75
			75 75 75 75 75 75 75 75 75 75 75 75 75 75 75 75 75 75
			75 75 75 75 75 75 75 75 75 75 75 75 75 75 75 75 75 75
			75 75 75 75 75 75 75 75 75 75 75 75 75 75 75 75 75 75
			75 75 75 75 75 75 75 75 75 75 75 75 75 75 75 75 75 75
			75 75 75 75 75 75 75 75 75 75 75 75 75 75 75 75 75 75
			75 75 75 75 75 75 75 75 75 75 75 75 75 75 75 75 75 75
			75 75 75 75 75 75 75 75 75 75 75 75 75 75 75 75 75 75
			75 75 75 75 75 75 75 75 75 75 75 75 75 75 75 75 75 75
			75 75 75 75 75 75 75 75 75 75 75 75 75 75 75 75 75 75
			75 75 75 75 75 75 75 75 75 75 75 75 75 75 75 75 75 75
			75 75 75 75 75 75 75 75 75 75 75 75 75 75 75 75 75 75
			75 75 75 75 75 75 75 75 75 75 75 75 75 75 75 75 75 75
			75 75 75 75 75 75 75 75 75 75 75 75 75 75 75 75 75 75
			75 75 75 75 75 75 75 75 75 75 75 75 75 75 75 75 75 75
			75 75 75 75 75 75 75 75 75 75 75 75 75 75 75 75 75 75
			75 75 75 75 75 75 75 75 75 75 75 75 75 75 75 75 75 75
			75 75 75 75 75 75 75 75 75 75 75 75 75 75 75 75 75 75
			75 75 75 75 75 75 75 75 75 75 75 75 75 75 75 75 75 75
			75 75 75 75 75 75 75 75 75 75 75 75 75 75 75 75 75 75
			75 75 75 75 75 75 75 75 75 75 75 75 75 75 75 75 75 75
			75 75 75 75 75 75 75 75 75 75 75 75 75 75 75 75 75 75
			75 75 75 75 75 75 75 75 75 75 75 75 75 75 75 75 75 75
			75 75 75 75 75 75 75 75 75 75 75 75 75 75 75 75 75 75
			75 75 75 75 75 75 75 75 75 75 75 75 75 75 75 75 75 75
			75 75 75 75 75 75 75 75 75 75 75 75 75 75 75 75 75 75
			>;

		PS_Config_Lmt_FW_Diff_N = <
			(-75) (-75) (-75) (-75) (-75) (-75) (-75) (-75) (-75) (-75) (-75) (-75) (-75) (-75) (-75) (-75) (-75) (-75)
			(-75) (-75) (-75) (-75) (-75) (-75) (-75) (-75) (-75) (-75) (-75) (-75) (-75) (-75) (-75) (-75) (-75) (-75)
			(-75) (-75) (-75) (-75) (-75) (-75) (-75) (-75) (-75) (-75) (-75) (-75) (-75) (-75) (-75) (-75) (-75) (-75)
			(-75) (-75) (-75) (-75) (-75) (-75) (-75) (-75) (-75) (-75) (-75) (-75) (-75) (-75) (-75) (-75) (-75) (-75)
			(-75) (-75) (-75) (-75) (-75) (-75) (-75) (-75) (-75) (-75) (-75) (-75) (-75) (-75) (-75) (-75) (-75) (-75)
			(-75) (-75) (-75) (-75) (-75) (-75) (-75) (-75) (-75) (-75) (-75) (-75) (-75) (-75) (-75) (-75) (-75) (-75)
			(-75) (-75) (-75) (-75) (-75) (-75) (-75) (-75) (-75) (-75) (-75) (-75) (-75) (-75) (-75) (-75) (-75) (-75)
			(-75) (-75) (-75) (-75) (-75) (-75) (-75) (-75) (-75) (-75) (-75) (-75) (-75) (-75) (-75) (-75) (-75) (-75)
			(-75) (-75) (-75) (-75) (-75) (-75) (-75) (-75) (-75) (-75) (-75) (-75) (-75) (-75) (-75) (-75) (-75) (-75)
			(-75) (-75) (-75) (-75) (-75) (-75) (-75) (-75) (-75) (-75) (-75) (-75) (-75) (-75) (-75) (-75) (-75) (-75)
			(-75) (-75) (-75) (-75) (-75) (-75) (-75) (-75) (-75) (-75) (-75) (-75) (-75) (-75) (-75) (-75) (-75) (-75)
			(-75) (-75) (-75) (-75) (-75) (-75) (-75) (-75) (-75) (-75) (-75) (-75) (-75) (-75) (-75) (-75) (-75) (-75)
			(-75) (-75) (-75) (-75) (-75) (-75) (-75) (-75) (-75) (-75) (-75) (-75) (-75) (-75) (-75) (-75) (-75) (-75)
			(-75) (-75) (-75) (-75) (-75) (-75) (-75) (-75) (-75) (-75) (-75) (-75) (-75) (-75) (-75) (-75) (-75) (-75)
			(-75) (-75) (-75) (-75) (-75) (-75) (-75) (-75) (-75) (-75) (-75) (-75) (-75) (-75) (-75) (-75) (-75) (-75)
			(-75) (-75) (-75) (-75) (-75) (-75) (-75) (-75) (-75) (-75) (-75) (-75) (-75) (-75) (-75) (-75) (-75) (-75)
			(-75) (-75) (-75) (-75) (-75) (-75) (-75) (-75) (-75) (-75) (-75) (-75) (-75) (-75) (-75) (-75) (-75) (-75)
			(-75) (-75) (-75) (-75) (-75) (-75) (-75) (-75) (-75) (-75) (-75) (-75) (-75) (-75) (-75) (-75) (-75) (-75)
			(-75) (-75) (-75) (-75) (-75) (-75) (-75) (-75) (-75) (-75) (-75) (-75) (-75) (-75) (-75) (-75) (-75) (-75)
			(-75) (-75) (-75) (-75) (-75) (-75) (-75) (-75) (-75) (-75) (-75) (-75) (-75) (-75) (-75) (-75) (-75) (-75)
			(-75) (-75) (-75) (-75) (-75) (-75) (-75) (-75) (-75) (-75) (-75) (-75) (-75) (-75) (-75) (-75) (-75) (-75)
			(-75) (-75) (-75) (-75) (-75) (-75) (-75) (-75) (-75) (-75) (-75) (-75) (-75) (-75) (-75) (-75) (-75) (-75)
			(-75) (-75) (-75) (-75) (-75) (-75) (-75) (-75) (-75) (-75) (-75) (-75) (-75) (-75) (-75) (-75) (-75) (-75)
			(-75) (-75) (-75) (-75) (-75) (-75) (-75) (-75) (-75) (-75) (-75) (-75) (-75) (-75) (-75) (-75) (-75) (-75)
			(-75) (-75) (-75) (-75) (-75) (-75) (-75) (-75) (-75) (-75) (-75) (-75) (-75) (-75) (-75) (-75) (-75) (-75)
			(-75) (-75) (-75) (-75) (-75) (-75) (-75) (-75) (-75) (-75) (-75) (-75) (-75) (-75) (-75) (-75) (-75) (-75)
			(-75) (-75) (-75) (-75) (-75) (-75) (-75) (-75) (-75) (-75) (-75) (-75) (-75) (-75) (-75) (-75) (-75) (-75)
			(-75) (-75) (-75) (-75) (-75) (-75) (-75) (-75) (-75) (-75) (-75) (-75) (-75) (-75) (-75) (-75) (-75) (-75)
			(-75) (-75) (-75) (-75) (-75) (-75) (-75) (-75) (-75) (-75) (-75) (-75) (-75) (-75) (-75) (-75) (-75) (-75)
			(-75) (-75) (-75) (-75) (-75) (-75) (-75) (-75) (-75) (-75) (-75) (-75) (-75) (-75) (-75) (-75) (-75) (-75)
			(-75) (-75) (-75) (-75) (-75) (-75) (-75) (-75) (-75) (-75) (-75) (-75) (-75) (-75) (-75) (-75) (-75) (-75)
			(-75) (-75) (-75) (-75) (-75) (-75) (-75) (-75) (-75) (-75) (-75) (-75) (-75) (-75) (-75) (-75) (-75) (-75)
			>;

		PS_Config_Diff_Test_Frame = <50>;

		PS_Config_Lmt_LPWG_Rawdata_P = <
			1920 1920 1920 1920 1920 1920 1920 1920 1920 1920 1920 1920 1920 1920 1920 1920 1920 1920
			1920 1920 1920 1920 1920 1920 1920 1920 1920 1920 1920 1920 1920 1920 1920 1920 1920 1920
			1920 1920 1920 1920 1920 1920 1920 1920 1920 1920 1920 1920 1920 1920 1920 1920 1920 1920
			1920 1920 1920 1920 1920 1920 1920 1920 1920 1920 1920 1920 1920 1920 1920 1920 1920 1920
			1920 1920 1920 1920 1920 1920 1920 1920 1920 1920 1920 1920 1920 1920 1920 1920 1920 1920
			1920 1920 1920 1920 1920 1920 1920 1920 1920 1920 1920 1920 1920 1920 1920 1920 1920 1920
			1920 1920 1920 1920 1920 1920 1920 1920 1920 1920 1920 1920 1920 1920 1920 1920 1920 1920
			1920 1920 1920 1920 1920 1920 1920 1920 1920 1920 1920 1920 1920 1920 1920 1920 1920 1920
			1920 1920 1920 1920 1920 1920 1920 1920 1920 1920 1920 1920 1920 1920 1920 1920 1920 1920
			1920 1920 1920 1920 1920 1920 1920 1920 1920 1920 1920 1920 1920 1920 1920 1920 1920 1920
			1920 1920 1920 1920 1920 1920 1920 1920 1920 1920 1920 1920 1920 1920 1920 1920 1920 1920
			1920 1920 1920 1920 1920 1920 1920 1920 1920 1920 1920 1920 1920 1920 1920 1920 1920 1920
			1920 1920 1920 1920 1920 1920 1920 1920 1920 1920 1920 1920 1920 1920 1920 1920 1920 1920
			1920 1920 1920 1920 1920 1920 1920 1920 1920 1920 1920 1920 1920 1920 1920 1920 1920 1920
			1920 1920 1920 1920 1920 1920 1920 1920 1920 1920 1920 1920 1920 1920 1920 1920 1920 1920
			1920 1920 1920 1920 1920 1920 1920 1920 1920 1920 1920 1920 1920 1920 1920 1920 1920 1920
			1920 1920 1920 1920 1920 1920 1920 1920 1920 1920 1920 1920 1920 1920 1920 1920 1920 1920
			1920 1920 1920 1920 1920 1920 1920 1920 1920 1920 1920 1920 1920 1920 1920 1920 1920 1920
			1920 1920 1920 1920 1920 1920 1920 1920 1920 1920 1920 1920 1920 1920 1920 1920 1920 1920
			1920 1920 1920 1920 1920 1920 1920 1920 1920 1920 1920 1920 1920 1920 1920 1920 1920 1920
			1920 1920 1920 1920 1920 1920 1920 1920 1920 1920 1920 1920 1920 1920 1920 1920 1920 1920
			1920 1920 1920 1920 1920 1920 1920 1920 1920 1920 1920 1920 1920 1920 1920 1920 1920 1920
			1920 1920 1920 1920 1920 1920 1920 1920 1920 1920 1920 1920 1920 1920 1920 1920 1920 1920
			1920 1920 1920 1920 1920 1920 1920 1920 1920 1920 1920 1920 1920 1920 1920 1920 1920 1920
			1920 1920 1920 1920 1920 1920 1920 1920 1920 1920 1920 1920 1920 1920 1920 1920 1920 1920
			1920 1920 1920 1920 1920 1920 1920 1920 1920 1920 1920 1920 1920 1920 1920 1920 1920 1920
			1920 1920 1920 1920 1920 1920 1920 1920 1920 1920 1920 1920 1920 1920 1920 1920 1920 1920
			1920 1920 1920 1920 1920 1920 1920 1920 1920 1920 1920 1920 1920 1920 1920 1920 1920 1920
			1920 1920 1920 1920 1920 1920 1920 1920 1920 1920 1920 1920 1920 1920 1920 1920 1920 1920
			1920 1920 1920 1920 1920 1920 1920 1920 1920 1920 1920 1920 1920 1920 1920 1920 1920 1920
			1920 1920 1920 1920 1920 1920 1920 1920 1920 1920 1920 1920 1920 1920 1920 1920 1920 1920
			1920 1920 1920 1920 1920 1920 1920 1920 1920 1920 1920 1920 1920 1920 1920 1920 1920 1920
			>;

		PS_Config_Lmt_LPWG_Rawdata_N = <
			240 240 240 240 240 240 240 240 240 240 240 240 240 240 240 240 240 240
			240 240 240 240 240 240 240 240 240 240 240 240 240 240 240 240 240 240
			240 240 240 240 240 240 240 240 240 240 240 240 240 240 240 240 240 240
			240 240 240 240 240 240 240 240 240 240 240 240 240 240 240 240 240 240
			240 240 240 240 240 240 240 240 240 240 240 240 240 240 240 240 240 240
			240 240 240 240 240 240 240 240 240 240 240 240 240 240 240 240 240 240
			240 240 240 240 240 240 240 240 240 240 240 240 240 240 240 240 240 240
			240 240 240 240 240 240 240 240 240 240 240 240 240 240 240 240 240 240
			240 240 240 240 240 240 240 240 240 240 240 240 240 240 240 240 240 240
			240 240 240 240 240 240 240 240 240 240 240 240 240 240 240 240 240 240
			240 240 240 240 240 240 240 240 240 240 240 240 240 240 240 240 240 240
			240 240 240 240 240 240 240 240 240 240 240 240 240 240 240 240 240 240
			240 240 240 240 240 240 240 240 240 240 240 240 240 240 240 240 240 240
			240 240 240 240 240 240 240 240 240 240 240 240 240 240 240 240 240 240
			240 240 240 240 240 240 240 240 240 240 240 240 240 240 240 240 240 240
			240 240 240 240 240 240 240 240 240 240 240 240 240 240 240 240 240 240
			240 240 240 240 240 240 240 240 240 240 240 240 240 240 240 240 240 240
			240 240 240 240 240 240 240 240 240 240 240 240 240 240 240 240 240 240
			240 240 240 240 240 240 240 240 240 240 240 240 240 240 240 240 240 240
			240 240 240 240 240 240 240 240 240 240 240 240 240 240 240 240 240 240
			240 240 240 240 240 240 240 240 240 240 240 240 240 240 240 240 240 240
			240 240 240 240 240 240 240 240 240 240 240 240 240 240 240 240 240 240
			240 240 240 240 240 240 240 240 240 240 240 240 240 240 240 240 240 240
			240 240 240 240 240 240 240 240 240 240 240 240 240 240 240 240 240 240
			240 240 240 240 240 240 240 240 240 240 240 240 240 240 240 240 240 240
			240 240 240 240 240 240 240 240 240 240 240 240 240 240 240 240 240 240
			240 240 240 240 240 240 240 240 240 240 240 240 240 240 240 240 240 240
			240 240 240 240 240 240 240 240 240 240 240 240 240 240 240 240 240 240
			240 240 240 240 240 240 240 240 240 240 240 240 240 240 240 240 240 240
			240 240 240 240 240 240 240 240 240 240 240 240 240 240 240 240 240 240
			240 240 240 240 240 240 240 240 240 240 240 240 240 240 240 240 240 240
			240 240 240 240 240 240 240 240 240 240 240 240 240 240 240 240 240 240
			>;

		PS_Config_Lmt_LPWG_Diff_P = <
			90 90 90 90 90 90 90 90 90 90 90 90 90 90 90 90 90 90
			90 90 90 90 90 90 90 90 90 90 90 90 90 90 90 90 90 90
			90 90 90 90 90 90 90 90 90 90 90 90 90 90 90 90 90 90
			90 90 90 90 90 90 90 90 90 90 90 90 90 90 90 90 90 90
			90 90 90 90 90 90 90 90 90 90 90 90 90 90 90 90 90 90
			90 90 90 90 90 90 90 90 90 90 90 90 90 90 90 90 90 90
			90 90 90 90 90 90 90 90 90 90 90 90 90 90 90 90 90 90
			90 90 90 90 90 90 90 90 90 90 90 90 90 90 90 90 90 90
			90 90 90 90 90 90 90 90 90 90 90 90 90 90 90 90 90 90
			90 90 90 90 90 90 90 90 90 90 90 90 90 90 90 90 90 90
			90 90 90 90 90 90 90 90 90 90 90 90 90 90 90 90 90 90
			90 90 90 90 90 90 90 90 90 90 90 90 90 90 90 90 90 90
			90 90 90 90 90 90 90 90 90 90 90 90 90 90 90 90 90 90
			90 90 90 90 90 90 90 90 90 90 90 90 90 90 90 90 90 90
			90 90 90 90 90 90 90 90 90 90 90 90 90 90 90 90 90 90
			90 90 90 90 90 90 90 90 90 90 90 90 90 90 90 90 90 90
			90 90 90 90 90 90 90 90 90 90 90 90 90 90 90 90 90 90
			90 90 90 90 90 90 90 90 90 90 90 90 90 90 90 90 90 90
			90 90 90 90 90 90 90 90 90 90 90 90 90 90 90 90 90 90
			90 90 90 90 90 90 90 90 90 90 90 90 90 90 90 90 90 90
			90 90 90 90 90 90 90 90 90 90 90 90 90 90 90 90 90 90
			90 90 90 90 90 90 90 90 90 90 90 90 90 90 90 90 90 90
			90 90 90 90 90 90 90 90 90 90 90 90 90 90 90 90 90 90
			90 90 90 90 90 90 90 90 90 90 90 90 90 90 90 90 90 90
			90 90 90 90 90 90 90 90 90 90 90 90 90 90 90 90 90 90
			90 90 90 90 90 90 90 90 90 90 90 90 90 90 90 90 90 90
			90 90 90 90 90 90 90 90 90 90 90 90 90 90 90 90 90 90
			90 90 90 90 90 90 90 90 90 90 90 90 90 90 90 90 90 90
			90 90 90 90 90 90 90 90 90 90 90 90 90 90 90 90 90 90
			90 90 90 90 90 90 90 90 90 90 90 90 90 90 90 90 90 90
			90 90 90 90 90 90 90 90 90 90 90 90 90 90 90 90 90 90
			90 90 90 90 90 90 90 90 90 90 90 90 90 90 90 90 90 90
			>;

		PS_Config_Lmt_LPWG_Diff_N = <
			(-90) (-90) (-90) (-90) (-90) (-90) (-90) (-90) (-90) (-90) (-90) (-90) (-90) (-90) (-90) (-90) (-90) (-90)
			(-90) (-90) (-90) (-90) (-90) (-90) (-90) (-90) (-90) (-90) (-90) (-90) (-90) (-90) (-90) (-90) (-90) (-90)
			(-90) (-90) (-90) (-90) (-90) (-90) (-90) (-90) (-90) (-90) (-90) (-90) (-90) (-90) (-90) (-90) (-90) (-90)
			(-90) (-90) (-90) (-90) (-90) (-90) (-90) (-90) (-90) (-90) (-90) (-90) (-90) (-90) (-90) (-90) (-90) (-90)
			(-90) (-90) (-90) (-90) (-90) (-90) (-90) (-90) (-90) (-90) (-90) (-90) (-90) (-90) (-90) (-90) (-90) (-90)
			(-90) (-90) (-90) (-90) (-90) (-90) (-90) (-90) (-90) (-90) (-90) (-90) (-90) (-90) (-90) (-90) (-90) (-90)
			(-90) (-90) (-90) (-90) (-90) (-90) (-90) (-90) (-90) (-90) (-90) (-90) (-90) (-90) (-90) (-90) (-90) (-90)
			(-90) (-90) (-90) (-90) (-90) (-90) (-90) (-90) (-90) (-90) (-90) (-90) (-90) (-90) (-90) (-90) (-90) (-90)
			(-90) (-90) (-90) (-90) (-90) (-90) (-90) (-90) (-90) (-90) (-90) (-90) (-90) (-90) (-90) (-90) (-90) (-90)
			(-90) (-90) (-90) (-90) (-90) (-90) (-90) (-90) (-90) (-90) (-90) (-90) (-90) (-90) (-90) (-90) (-90) (-90)
			(-90) (-90) (-90) (-90) (-90) (-90) (-90) (-90) (-90) (-90) (-90) (-90) (-90) (-90) (-90) (-90) (-90) (-90)
			(-90) (-90) (-90) (-90) (-90) (-90) (-90) (-90) (-90) (-90) (-90) (-90) (-90) (-90) (-90) (-90) (-90) (-90)
			(-90) (-90) (-90) (-90) (-90) (-90) (-90) (-90) (-90) (-90) (-90) (-90) (-90) (-90) (-90) (-90) (-90) (-90)
			(-90) (-90) (-90) (-90) (-90) (-90) (-90) (-90) (-90) (-90) (-90) (-90) (-90) (-90) (-90) (-90) (-90) (-90)
			(-90) (-90) (-90) (-90) (-90) (-90) (-90) (-90) (-90) (-90) (-90) (-90) (-90) (-90) (-90) (-90) (-90) (-90)
			(-90) (-90) (-90) (-90) (-90) (-90) (-90) (-90) (-90) (-90) (-90) (-90) (-90) (-90) (-90) (-90) (-90) (-90)
			(-90) (-90) (-90) (-90) (-90) (-90) (-90) (-90) (-90) (-90) (-90) (-90) (-90) (-90) (-90) (-90) (-90) (-90)
			(-90) (-90) (-90) (-90) (-90) (-90) (-90) (-90) (-90) (-90) (-90) (-90) (-90) (-90) (-90) (-90) (-90) (-90)
			(-90) (-90) (-90) (-90) (-90) (-90) (-90) (-90) (-90) (-90) (-90) (-90) (-90) (-90) (-90) (-90) (-90) (-90)
			(-90) (-90) (-90) (-90) (-90) (-90) (-90) (-90) (-90) (-90) (-90) (-90) (-90) (-90) (-90) (-90) (-90) (-90)
			(-90) (-90) (-90) (-90) (-90) (-90) (-90) (-90) (-90) (-90) (-90) (-90) (-90) (-90) (-90) (-90) (-90) (-90)
			(-90) (-90) (-90) (-90) (-90) (-90) (-90) (-90) (-90) (-90) (-90) (-90) (-90) (-90) (-90) (-90) (-90) (-90)
			(-90) (-90) (-90) (-90) (-90) (-90) (-90) (-90) (-90) (-90) (-90) (-90) (-90) (-90) (-90) (-90) (-90) (-90)
			(-90) (-90) (-90) (-90) (-90) (-90) (-90) (-90) (-90) (-90) (-90) (-90) (-90) (-90) (-90) (-90) (-90) (-90)
			(-90) (-90) (-90) (-90) (-90) (-90) (-90) (-90) (-90) (-90) (-90) (-90) (-90) (-90) (-90) (-90) (-90) (-90)
			(-90) (-90) (-90) (-90) (-90) (-90) (-90) (-90) (-90) (-90) (-90) (-90) (-90) (-90) (-90) (-90) (-90) (-90)
			(-90) (-90) (-90) (-90) (-90) (-90) (-90) (-90) (-90) (-90) (-90) (-90) (-90) (-90) (-90) (-90) (-90) (-90)
			(-90) (-90) (-90) (-90) (-90) (-90) (-90) (-90) (-90) (-90) (-90) (-90) (-90) (-90) (-90) (-90) (-90) (-90)
			(-90) (-90) (-90) (-90) (-90) (-90) (-90) (-90) (-90) (-90) (-90) (-90) (-90) (-90) (-90) (-90) (-90) (-90)
			(-90) (-90) (-90) (-90) (-90) (-90) (-90) (-90) (-90) (-90) (-90) (-90) (-90) (-90) (-90) (-90) (-90) (-90)
			(-90) (-90) (-90) (-90) (-90) (-90) (-90) (-90) (-90) (-90) (-90) (-90) (-90) (-90) (-90) (-90) (-90) (-90)
			(-90) (-90) (-90) (-90) (-90) (-90) (-90) (-90) (-90) (-90) (-90) (-90) (-90) (-90) (-90) (-90) (-90) (-90)
			>;
	}; /* novatek-mp-criteria-hlt */
    };
};
//#endif
/* TOUCH end */

&i2c0 {
      lcm_bias@3e{
               compatible = "LCD_BIAS_SM5109","LCD_BIAS_OCP2130";
               reg = <0x3e>;
               status = "okay";
       };
};
&i2c2 {
	clock-frequency = <400000>;

	mtk-usb@60 {
		compatible = "mediatek,mtk-usb";
		reg = <0x60>;
		status = "okay";
	};
};

//#ifdef ODM_WT_EDIT
//Yuexiu.Wu@ODM_WT.WCN.NFC, 2019/10/05, Add for NFC bringup
//Yuexiu.Wu@ODM_WT.WCN.NFC.Basic.1941873,2019/12/14,delete for use MTK driver
/*&i2c3{
     pn544:nfc@28 {
         compatible = "nxp,pn544";
         reg = <0x28>;
         pn544-irq = <&pio 6 0x0>;
         pn544-ven = <&pio 54 0x0>;
         pn544-fw-dwnld = <&pio 19 0x0>;
         pn544-clkreq = <&pio 11 0x0>;
         status = "okay";
    };
};*/
 //#endif


/* accdet start */
&accdet {
	/* accdet micbias voltage: 0x07,2.7v;0x05,2.5v;0x02,1.9v */
	/* #ifdef ODM_WT_EDIT */
	/* Zengchao.Duan@ODM_WT.mm.audiodriver.Machine, 2019/10/28, Add for setting micbias voltage to 2.7v */
	accdet-mic-vol = <7>;
	/* #endif */
	headset-mode-setting = <0x500 0x500 1 0x1f0 0x800 0x800 0x20 0x44>;
	accdet-plugout-debounce = <1>;
	/*1:ACC mode, 2:low cost without in bias, 6:low cost with in bias*/
	accdet-mic-mode = <1>;
	/* eint_level_trigger: 8,LEVEL_LOW(DEF) ;4,LV_HIGH;others,LV_LOW */
	headset-eint-level-pol = <8>;
	/*0--MD_MAX--UP_MAX--DW_MAX*/
	headset-three-key-threshold = <0 80 220 400>;
	headset-three-key-threshold-CDD = <0 121 192 600>;
	/*0--MD_MAX--VOICE_MAX--UP_MAX--DW_MAX*/
	headset-four-key-threshold = <0 58 121 192 400>;
	status = "okay";
};
/* accdet end */

&mt6370_pmu {
	mt6370,intr_gpio_num = <20>; /* direct defined GPIO num */
	mt6370,intr_gpio = <&pio 20 0x0>;
};
&mt6370_typec {
	mt6370pd,intr_gpio_num = <41>; /* direct defined GPIO num */
	mt6370pd,intr_gpio = <&pio 41 0x0>;
};

/* CONSYS GPIO standardization */
&pio {
	consys_pins_default: consys_default {
	};
	gpslna_pins_init: gpslna@0 {
            //#ifdef ODM_WT_EDIT
            //Yuexiu.Wu@ODM_WT.WCN.NFC.Basic.1941873,2019/10/08,assign new GPS LNA gpio
            pins_cmd_dat {
                pinmux = <PINMUX_GPIO53__FUNC_GPIO53>;
                //#ifndef VENDOR_EDIT
                //Wenjie.Liu@PSW.CN.GPS.Hardware.Power.1202743, 2017/12/29,
                //modify for: [GPS_LNA gpio's output direction is out]
                /*
                slew-rate = <0>;
                */
                slew-rate = <1>;
                //#endif /* VENDOR_EDIT */
                bias-disable;
                output-low;
            };
            //#endif /* ODM_WT_EDIT */
	};
	gpslna_pins_oh: gpslna@1 {
            //#ifdef ODM_WT_EDIT
            //Yuexiu.Wu@ODM_WT.WCN.NFC.Basic.1941873,2019/10/08,assign new GPS LNA gpio
            pins_cmd_dat {
                pinmux = <PINMUX_GPIO53__FUNC_GPIO53>;
                slew-rate = <1>;
                output-high;
            };
            //#endif /* ODM_WT_EDIT */
	};
	gpslna_pins_ol: gpslna@2 {
            //#ifdef ODM_WT_EDIT
            //Yuexiu.Wu@ODM_WT.WCN.NFC.Basic.1941873,2019/10/08,assign new GPS LNA gpio
            pins_cmd_dat {
                pinmux = <PINMUX_GPIO53__FUNC_GPIO53>;
                slew-rate = <1>;
                output-low;
            };
            //#endif /* ODM_WT_EDIT */
	};
};
&consys {
	pinctrl-names = "default", "gps_lna_state_init",
		"gps_lna_state_oh", "gps_lna_state_ol";
	pinctrl-0 = <&consys_pins_default>;
	pinctrl-1 = <&gpslna_pins_init>;
	pinctrl-2 = <&gpslna_pins_oh>;
	pinctrl-3 = <&gpslna_pins_ol>;
	status = "okay";
};
/* CONSYS end */

/* IRTX GPIO Start */
&irtx_pwm {
	pinctrl-names = "irtx_gpio_led_default", "irtx_gpio_led_set";
	pinctrl-0 = <&irtx_gpio_led_default>;
	pinctrl-1 = <&irtx_gpio_led_set>;
	status = "okay";
};
&pio {
	/* IRTX GPIO Settings -Start */
	/* default: GPIO0, output, high */
	irtx_gpio_led_default:irtx_gpio_led_def@gpio12 {
		pins_cmd_dat {
			pinmux = <PINMUX_GPIO12__FUNC_GPIO12>;
			slew-rate = <1>;
			bias-disable;
			output-low;
			input-schmitt-enable = <0>;
		};
	};

	irtx_gpio_led_set:irtx_gpio_led_set@gpio12 {
		pins_cmd_dat {
			pinmux = <PINMUX_GPIO12__FUNC_PWM0>;
			slew-rate = <1>;
			output-high;
		};
	};
}; /* IRTX GPIO Settings -End */

/* DISPSYS GPIO standardization */
&pio {
	mtkfb_pins_lcm_rst_out1_gpio: lcm_rst_out1_gpio {
		pins_cmd_dat {
			pinmux = <PINMUX_GPIO45__FUNC_GPIO45>;
			slew-rate = <1>;
			output-high;
		};
	};

	mtkfb_pins_lcm_rst_out0_gpio: lcm_rst_out0_gpio {
		pins_cmd_dat {
			pinmux = <PINMUX_GPIO45__FUNC_GPIO45>;
			slew-rate = <1>;
			output-low;
		};
	};

	mtkfb_pins_lcm_dsi_te: lcm_dsi_te {
		pins_cmd_dat {
			pinmux = <PINMUX_GPIO44__FUNC_DSI_TE>;
		};
	};
};

/*&mtkfb {
	pinctrl-names =
		"lcm_rst_out1_gpio", "lcm_rst_out0_gpio",
		"mode_te_te";
	pinctrl-0 = <&mtkfb_pins_lcm_rst_out1_gpio>;
	pinctrl-1 = <&mtkfb_pins_lcm_rst_out0_gpio>;
	pinctrl-2 = <&mtkfb_pins_lcm_dsi_te>;
	status = "okay";
};*/
/* Hao.Liang@ODM_WT.MM.Display.Lcd, 2019/9/25, LCD bringup */
/* DISPSYS GPIO standardization */
&mtkfb {
        pinctrl-names = "lcm_rst_out0_gpio", "lcm_rst_out1_gpio", "lcd_bias_enp0_gpio", "lcd_bias_enp1_gpio",
			"lcd_bias_enn0_gpio", "lcd_bias_enn1_gpio", "lcd_vddio18_en0_gpio", "lcd_vddio18_en1_gpio";

	pinctrl-0 = <&mtkfb_pins_lcm_reset0>;
	pinctrl-1 = <&mtkfb_pins_lcm_reset1>;
	pinctrl-2 = <&mtkfb_pins_lcd_bias_enp0>;
	pinctrl-3 = <&mtkfb_pins_lcd_bias_enp1>;
	pinctrl-4 = <&mtkfb_pins_lcd_bias_enn0>;
	pinctrl-5 = <&mtkfb_pins_lcd_bias_enn1>;
	//pinctrl-6 = <&mtkfb_pins_lcd_vddio18_en0>;
	//pinctrl-7 = <&mtkfb_pins_lcd_vddio18_en1>;
        status = "okay";
};

&pio {
        mtkfb_pins_lcm_reset0: lcm_rst_out0_gpio {
                pins_cmd_dat {
                        pinmux = <PINMUX_GPIO45__FUNC_GPIO45>;
                        slew-rate = <1>;
                        output-low;
                };
        };
        mtkfb_pins_lcm_reset1: lcm_rst_out1_gpio {
                pins_cmd_dat {
                        pinmux = <PINMUX_GPIO45__FUNC_GPIO45>;
                        slew-rate = <1>;
                        output-high;
                };
        };

	mtkfb_pins_lcd_bias_enp0: lcd_bias_enp0_gpio {
                pins_cmd_dat {
                        pinmux = <PINMUX_GPIO169__FUNC_GPIO169>;
                        slew-rate = <1>;
                        output-low;
                };
        };
	mtkfb_pins_lcd_bias_enp1: lcd_bias_enp1_gpio {
                pins_cmd_dat {
                        pinmux = <PINMUX_GPIO169__FUNC_GPIO169>;
                        slew-rate = <1>;
                        output-high;
                };
        };

	mtkfb_pins_lcd_bias_enn0: lcd_bias_enn0_gpio {
                pins_cmd_dat {
                        pinmux = <PINMUX_GPIO165__FUNC_GPIO165>;
                        slew-rate = <1>;
                        output-low;
                };
        };
	mtkfb_pins_lcd_bias_enn1: lcd_bias_enn1_gpio {
                pins_cmd_dat {
                        pinmux = <PINMUX_GPIO165__FUNC_GPIO165>;
                        slew-rate = <1>;
                        output-high;
                };
        };

/*	mtkfb_pins_lcd_vddio18_en0: lcd_vddio18_en0_gpio {
                pins_cmd_dat {
                        pinmux = <PINMUX_GPIO170__FUNC_GPIO170>;
                        slew-rate = <1>;
                        output-low;
                };
        };
	mtkfb_pins_lcd_vddio18_en1: lcd_vddio18_en1_gpio {
                pins_cmd_dat {
                        pinmux = <PINMUX_GPIO170__FUNC_GPIO170>;
                        slew-rate = <1>;
                        output-high;
                };
        };*/
};
/* Hao.Liang@ODM_WT.MM.Display.Lcd, 2019/9/25, LCD bringup */
/* DISPSYS GPIO standardization end*/

/*Shouli.Wang@ODM_WT.BSP.CHG 2019/9/25, charger bringup start*/
&bat_gm30 {
		io-channels = <&auxadc 2>;
		io-channel-names = "batteryID-channel";	
};
#include "rt9471_single.dtsi"
/*Shouli.Wang@ODM_WT.BSP.CHG 2019/9/25, charger bringup end*/
//#ifdef ODM_WT_EDIT
/*Shouli.Wang@ODM_WT.BSP.CHG 2019/10/07, modify monet charger params*/
&charger {
	ac_charger_input_current = <2000000>;
	ac_charger_current = <2000000>;
	/delete-node/ enable_type_c;
};
//#endif /*ODM_WT_EDIT*/

//#ifdef ODM_WT_EDIT
//Mingyao.Xie@ODM_WT.BSP.Storage.Usb, 2018/08/07, Modify for OTG
&otg_iddig	{
		compatible = "mediatek,usb_iddig_bi_eint";
		interrupt-parent = <&pio>;
		interrupts = <147 IRQ_TYPE_LEVEL_LOW 147 0>;
		pinctrl-names ="otg_iddg_high", "otg_gpio_low";
		pinctrl-0 = <&otg_iddg_high>;
		pinctrl-1 = <&otg_gpio_low>;
		status = "okay";

	};

&pio {
    otg_iddg_high: otg_iddg_high {
        pins_cmd_dat {
            pinmux = <PINMUX_GPIO41__FUNC_IDDIG>;
        };
    };
    otg_gpio_low: otg_gpio_low {
        pins_cmd_dat {
            pinmux = <PINMUX_GPIO41__FUNC_GPIO41>;
            slew-rate = <1>;
            input-low;
        };
    };
};
//#endif

//#ifdef ODM_WT_EDIT
/*Shouli.Wang@ODM_WT.BSP.CHG 2019/12/03, add for key function compatible*/
&keypad {
	mediatek,kpd-sw-rstkey_1  = <115>;
	mediatek,kpd-hw-init-map_1 = <0 114 0 0 0 0 0 0 0 0 0 0 0 0 0 0 0 0 0 0 0 0 0 0 0 0 0 0 0 0 0 0 0 0 0 0 0 0 0 0 0 0 0 0 0 0 0 0 0 0 0 0 0 0 0 0 0 0 0 0 0 0 0 0 0 0 0 0 0 0 0 0 >;
};
//#endif /*ODM_WT_EDIT*/

#include <oppo6769_19741/cust.dtsi>
#include "cust_mt6768_camera.dtsi"
/*End of this file, DO NOT ADD ANYTHING HERE*/
